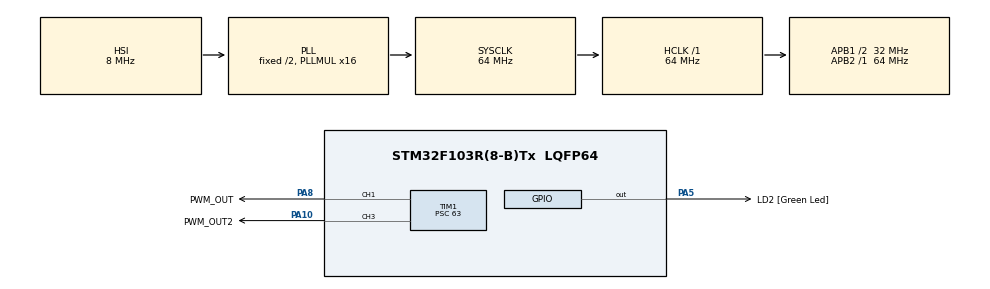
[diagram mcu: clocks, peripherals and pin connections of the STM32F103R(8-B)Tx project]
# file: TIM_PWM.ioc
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Mcu.Family=STM32F1
Mcu.Name=STM32F103R(8-B)Tx
Mcu.Package=LQFP64
NVIC.PriorityGroup=NVIC_PRIORITYGROUP_4
PA10.GPIO_Label=PWM_OUT2
PA10.GPIO_Speed=GPIO_SPEED_FREQ_HIGH
PA10.Signal=S_TIM1_CH3
PA13.GPIO_Label=TMS
PA13.Mode=Serial_Wire
PA13.Signal=SYS_JTMS-SWDIO
PA14.GPIO_Label=TCK
PA14.Mode=Serial_Wire
PA14.Signal=SYS_JTCK-SWCLK
PA5.GPIO_Label=LD2 [Green Led]
PA5.GPIO_ModeDefaultOutputPP=GPIO_MODE_OUTPUT_PP
PA5.GPIO_PuPd=GPIO_NOPULL
PA5.GPIO_Speed=GPIO_SPEED_FREQ_LOW
PA5.Signal=GPIO_Output
PA8.GPIO_Label=PWM_OUT
PA8.GPIO_Speed=GPIO_SPEED_FREQ_HIGH
PA8.Signal=S_TIM1_CH1
PB3.GPIO_Label=SWO
PB3.Signal=SYS_JTDO-TRACESWO
PC14-OSC32_IN.Mode=LSE-External-Oscillator
PC14-OSC32_IN.Signal=RCC_OSC32_IN
PC15-OSC32_OUT.Mode=LSE-External-Oscillator
PC15-OSC32_OUT.Signal=RCC_OSC32_OUT
PD0-OSC_IN.Mode=HSE-External-Clock-Source
PD0-OSC_IN.Signal=RCC_OSC_IN
PD1-OSC_OUT.Mode=HSE-External-Clock-Source
PD1-OSC_OUT.Signal=RCC_OSC_OUT
ProjectManager.HeapSize=0x200
ProjectManager.StackSize=0x400
ProjectManager.TargetToolchain=STM32CubeIDE
RCC.AHBFreq_Value=64000000
RCC.APB1CLKDivider=RCC_HCLK_DIV2
RCC.APB1Freq_Value=32000000
RCC.APB1TimFreq_Value=64000000
RCC.APB2Freq_Value=64000000
RCC.APB2TimFreq_Value=64000000
RCC.HCLKFreq_Value=64000000
RCC.PLLMUL=RCC_PLL_MUL16
RCC.RTCClockSelection=RCC_RTCCLKSOURCE_LSE
RCC.SYSCLKFreq_VALUE=64000000
RCC.SYSCLKSource=RCC_SYSCLKSOURCE_PLLCLK
RCC.USBFreq_Value=64000000
SH.S_TIM1_CH1.0=TIM1_CH1,PWM Generation1 CH1
SH.S_TIM1_CH3.0=TIM1_CH3,PWM Generation3 CH3
TIM1.AutoReloadPreload=TIM_AUTORELOAD_PRELOAD_ENABLE
TIM1.Channel-PWM\ Generation1\ CH1=TIM_CHANNEL_1
TIM1.Channel-PWM\ Generation3\ CH3=TIM_CHANNEL_3
TIM1.Period=999
TIM1.Prescaler=63
board=NUCLEO-F103RB

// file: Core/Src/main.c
/* USER CODE BEGIN Header */
/**
 ******************************************************************************
 * @file           : main.c
 * @brief          : Main program body
 ******************************************************************************
 * @attention
 *
 * Copyright (c) 2026 STMicroelectronics.
 * All rights reserved.
 *
 * This software is licensed under terms that can be found in the LICENSE file
 * in the root directory of this software component.
 * If no LICENSE file comes with this software, it is provided AS-IS.
 *
 ******************************************************************************
 */
/**
 * 03_Link_PWM_Meter_HAL_c  —  [계층: HAL]  TIM1_CH1(PA8=D7) 1kHz PWM, 듀티를 3초마다 5단계로 변경
 *                              (DE1-SoC 연동 실습 3: FPGA 가 PWM 의 주기와 High 시간을 0.1 us 단위로 측정)
 *
 * 기반: 06_Timers_RTC/05_TIM_PWM. CubeMX 설정(.ioc)은 그대로이고 main.c 의 USER CODE 영역만 고쳤다.
 *
 * 동작
 *   TIM1->CCR1 을 100, 250, 500, 750, 900 순으로 3초마다 바꾼다 (듀티 10, 25, 50, 75, 90 %).
 *   FPGA(fpga/lab3_top.v)는 HEX5~HEX0 에 주기(SW0=0) 또는 High 시간(SW0=1)을 표시한다.
 *   기대값: 주기 010000 (1000.0 us), High = CCR1 x 10 (예: CCR1=250 -> 002500)
 *
 * 배선: D7 (PA8, TIM1_CH1) -> DE1-SoC JP1 3번 (GPIO_0[2], PIN_AD17),  GND 공통
 *   주의: .ioc 설정대로 TIM1_CH3(PA10 = D2)에도 PWM 출력이 켜진다 (CCR3 = 0 이라 계속 Low).
 *         실습 2의 FPGA 회로는 D2 선을 출력으로 구동하므로, 이 프로그램을 올리기 전에 D2 선을 뺀다.
 *
 * PWM 주파수/듀티 계산
 *   TIM1 클럭 = 64MHz (APB2=64MHz, 분주비 == 1 이므로 타이머 클럭 x1)
 *   PSC = 64-1   -> 카운터 클럭 1MHz, 1카운트 = 1 us  (TIM1->PSC)
 *   ARR = 1000-1 -> 주기 1000 카운트 = 1ms = 1kHz        (TIM1->ARR)
 *   CCR1 = High 시간(us)  (TIM1->CCR1),  듀티% = CCR1 / (ARR+1) x 100
 *   CCMR1.OC1M = 110 (PWM mode 1: CNT < CCR1 이면 High), CCER.CC1E = 1 (출력 활성)
 *
 * TIM1 은 Advanced 타이머 : 출력이 나오려면 BDTR.MOE = 1 이어야 한다.
 *   HAL_TIM_PWM_Start() 가 내부에서 __HAL_TIM_MOE_ENABLE() 로 MOE 를 세트한다.
 *
 * 인터럽트/콜백: 쓰지 않는다 (PWM 은 타이머 하드웨어가 파형을 생성). ISR 은 SysTick_Handler(HAL_Delay 용)뿐이다.
 */
/* USER CODE END Header */
#include "main.h"

TIM_HandleTypeDef htim1;

void SystemClock_Config(void);
static void MX_GPIO_Init(void);
static void MX_TIM1_Init(void);

int main(void)
{

  /* MCU Configuration--------------------------------------------------------*/

  /* Reset of all peripherals, Initializes the Flash interface and the Systick. */
  HAL_Init();

  /* Configure the system clock */
  SystemClock_Config();

  /* Initialize all configured peripherals */
  MX_GPIO_Init();
  MX_TIM1_Init();
  /* USER CODE BEGIN 2 */
  /* PWM 시작: CCER.CC1E/CC3E = 1 (CH1/CH3 출력 활성), BDTR.MOE = 1 (TIM1 메인 출력 활성),
     CR1.CEN = 1 (카운터 시작) */
  if (HAL_TIM_PWM_Start(&htim1, TIM_CHANNEL_1) != HAL_OK) Error_Handler();
  if (HAL_TIM_PWM_Start(&htim1, TIM_CHANNEL_3) != HAL_OK) Error_Handler();
  /* USER CODE END 2 */

  /* Infinite loop */
  while (1)
  {

    /* USER CODE BEGIN 3 */
    /* TIM1->CCR1에 넣을 값. 1카운트 = 1 us이므로 High 시간(us)과 같다.
     * 듀티 = CCR1 / (ARR + 1) = 10, 25, 50, 75, 90 % */
    static const uint16_t ccr_table[] = {100, 250, 500, 750, 900};
    static uint8_t k = 0;

    __HAL_TIM_SET_COMPARE(&htim1, TIM_CHANNEL_1, ccr_table[k]);   /* TIM1->CCR1 = 표의 값 */
    k = (k + 1) % 5;
    HAL_Delay(3000);                                              /* 3초 유지 */
  }
  /* USER CODE END 3 */
}

void SystemClock_Config(void)
{
  RCC_OscInitTypeDef RCC_OscInitStruct = {0};
  RCC_ClkInitTypeDef RCC_ClkInitStruct = {0};

  /** Initializes the RCC Oscillators according to the specified parameters
  * in the RCC_OscInitTypeDef structure.
  */
  RCC_OscInitStruct.OscillatorType = RCC_OSCILLATORTYPE_HSI;
  RCC_OscInitStruct.HSIState = RCC_HSI_ON;
  RCC_OscInitStruct.HSICalibrationValue = RCC_HSICALIBRATION_DEFAULT;
  RCC_OscInitStruct.PLL.PLLState = RCC_PLL_ON;
  RCC_OscInitStruct.PLL.PLLSource = RCC_PLLSOURCE_HSI_DIV2;
  RCC_OscInitStruct.PLL.PLLMUL = RCC_PLL_MUL16;
  if (HAL_RCC_OscConfig(&RCC_OscInitStruct) != HAL_OK)
  {
    Error_Handler();
  }

  /** Initializes the CPU, AHB and APB buses clocks
  */
  RCC_ClkInitStruct.ClockType = RCC_CLOCKTYPE_HCLK|RCC_CLOCKTYPE_SYSCLK
                              |RCC_CLOCKTYPE_PCLK1|RCC_CLOCKTYPE_PCLK2;
  RCC_ClkInitStruct.SYSCLKSource = RCC_SYSCLKSOURCE_PLLCLK;
  RCC_ClkInitStruct.AHBCLKDivider = RCC_SYSCLK_DIV1;
  RCC_ClkInitStruct.APB1CLKDivider = RCC_HCLK_DIV2;
  RCC_ClkInitStruct.APB2CLKDivider = RCC_HCLK_DIV1;

  if (HAL_RCC_ClockConfig(&RCC_ClkInitStruct, FLASH_LATENCY_2) != HAL_OK)
  {
    Error_Handler();
  }
}

static void MX_TIM1_Init(void)
{

  TIM_MasterConfigTypeDef sMasterConfig = {0};
  TIM_OC_InitTypeDef sConfigOC = {0};
  TIM_BreakDeadTimeConfigTypeDef sBreakDeadTimeConfig = {0};

  htim1.Instance = TIM1;
  htim1.Init.Prescaler = 63;
  htim1.Init.CounterMode = TIM_COUNTERMODE_UP;
  htim1.Init.Period = 999;
  htim1.Init.ClockDivision = TIM_CLOCKDIVISION_DIV1;
  htim1.Init.RepetitionCounter = 0;
  htim1.Init.AutoReloadPreload = TIM_AUTORELOAD_PRELOAD_ENABLE;
  if (HAL_TIM_PWM_Init(&htim1) != HAL_OK)
  {
    Error_Handler();
  }
  sMasterConfig.MasterOutputTrigger = TIM_TRGO_RESET;
  sMasterConfig.MasterSlaveMode = TIM_MASTERSLAVEMODE_DISABLE;
  if (HAL_TIMEx_MasterConfigSynchronization(&htim1, &sMasterConfig) != HAL_OK)
  {
    Error_Handler();
  }
  sConfigOC.OCMode = TIM_OCMODE_PWM1;
  sConfigOC.Pulse = 0;
  sConfigOC.OCPolarity = TIM_OCPOLARITY_HIGH;
  sConfigOC.OCNPolarity = TIM_OCNPOLARITY_HIGH;
  sConfigOC.OCFastMode = TIM_OCFAST_DISABLE;
  sConfigOC.OCIdleState = TIM_OCIDLESTATE_RESET;
  sConfigOC.OCNIdleState = TIM_OCNIDLESTATE_RESET;
  if (HAL_TIM_PWM_ConfigChannel(&htim1, &sConfigOC, TIM_CHANNEL_1) != HAL_OK)
  {
    Error_Handler();
  }
  if (HAL_TIM_PWM_ConfigChannel(&htim1, &sConfigOC, TIM_CHANNEL_3) != HAL_OK)
  {
    Error_Handler();
  }
  sBreakDeadTimeConfig.OffStateRunMode = TIM_OSSR_DISABLE;
  sBreakDeadTimeConfig.OffStateIDLEMode = TIM_OSSI_DISABLE;
  sBreakDeadTimeConfig.LockLevel = TIM_LOCKLEVEL_OFF;
  sBreakDeadTimeConfig.DeadTime = 0;
  sBreakDeadTimeConfig.BreakState = TIM_BREAK_DISABLE;
  sBreakDeadTimeConfig.BreakPolarity = TIM_BREAKPOLARITY_HIGH;
  sBreakDeadTimeConfig.AutomaticOutput = TIM_AUTOMATICOUTPUT_DISABLE;
  if (HAL_TIMEx_ConfigBreakDeadTime(&htim1, &sBreakDeadTimeConfig) != HAL_OK)
  {
    Error_Handler();
  }
  /* USER CODE BEGIN TIM1_Init 2 */
  /* PSC=64-1 -> 1MHz, ARR=1000-1 -> 1kHz, CCR1/CCR3 초기값 0 (OC1M/OC3M=110 PWM1, CR1.ARPE=1)
     BDTR: DTG=0, BKE=0, AOE=0 -> MOE 는 HAL_TIM_PWM_Start() 에서 세트 */
  /* USER CODE END TIM1_Init 2 */
  HAL_TIM_MspPostInit(&htim1);

}

static void MX_GPIO_Init(void)
{
  GPIO_InitTypeDef GPIO_InitStruct = {0};

  /* GPIO Ports Clock Enable */
  __HAL_RCC_GPIOC_CLK_ENABLE();
  __HAL_RCC_GPIOD_CLK_ENABLE();
  __HAL_RCC_GPIOA_CLK_ENABLE();
  __HAL_RCC_GPIOB_CLK_ENABLE();

  /*Configure GPIO pin Output Level */
  HAL_GPIO_WritePin(LD2_GPIO_Port, LD2_Pin, GPIO_PIN_RESET);

  /*Configure GPIO pin : LD2_Pin */
  GPIO_InitStruct.Pin = LD2_Pin;
  GPIO_InitStruct.Mode = GPIO_MODE_OUTPUT_PP;
  GPIO_InitStruct.Pull = GPIO_NOPULL;
  GPIO_InitStruct.Speed = GPIO_SPEED_FREQ_LOW;
  HAL_GPIO_Init(LD2_GPIO_Port, &GPIO_InitStruct);

}

void Error_Handler(void)
{
  __disable_irq();
  while (1) {
  }
}
#ifdef USE_FULL_ASSERT
/**
  * @brief  Reports the name of the source file and the source line number
  *         where the assert_param error has occurred.
  * @param  file: pointer to the source file name
  * @param  line: assert_param error line source number
  * @retval None
  */
void assert_failed(uint8_t *file, uint32_t line)
{
  /* USER CODE BEGIN 6 */
  /* User can add his own implementation to report the file name and line
     number, ex: printf("Wrong parameters value: file %s on line %d\r\n", file,
     line) */
  /* USER CODE END 6 */
}
#endif /* USE_FULL_ASSERT */
